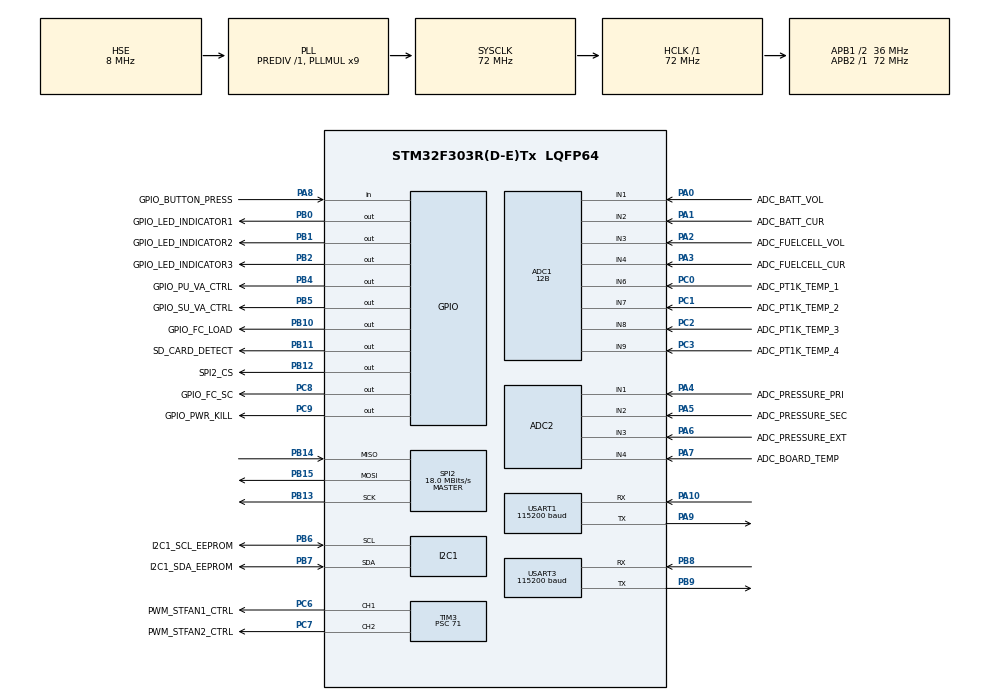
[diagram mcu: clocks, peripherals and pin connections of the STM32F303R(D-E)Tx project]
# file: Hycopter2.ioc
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ADC1.Channel-0\#ChannelRegularConversion=ADC_CHANNEL_1
ADC1.Channel-1\#ChannelRegularConversion=ADC_CHANNEL_2
ADC1.Channel-2\#ChannelRegularConversion=ADC_CHANNEL_3
ADC1.Channel-3\#ChannelRegularConversion=ADC_CHANNEL_4
ADC1.Channel-4\#ChannelRegularConversion=ADC_CHANNEL_6
ADC1.Channel-5\#ChannelRegularConversion=ADC_CHANNEL_7
ADC1.Channel-6\#ChannelRegularConversion=ADC_CHANNEL_8
ADC1.Channel-7\#ChannelRegularConversion=ADC_CHANNEL_9
ADC1.ClockPrescaler=ADC_CLOCK_ASYNC_DIV1
ADC1.ContinuousConvMode=DISABLE
ADC1.DMAContinuousRequests=ENABLE
ADC1.DataAlign=ADC_DATAALIGN_RIGHT
ADC1.DiscontinuousConvMode=DISABLE
ADC1.EOCSelection=ADC_EOC_SINGLE_CONV
ADC1.EnableAnalogWatchDog1=false
ADC1.EnableAnalogWatchDog2=false
ADC1.EnableAnalogWatchDog3=false
ADC1.EnableInjectedConversion=DISABLE
ADC1.EnableRegularConversion=ENABLE
ADC1.ExternalTrigConv=ADC_SOFTWARE_START
ADC1.ExternalTrigConvEdge=ADC_EXTERNALTRIGCONVEDGE_NONE
ADC1.LowPowerAutoWait=DISABLE
ADC1.NbrOfConversion=8
ADC1.NbrOfConversionFlag=1
ADC1.Offset-0\#ChannelRegularConversion=0
ADC1.Offset-1\#ChannelRegularConversion=0
ADC1.Offset-2\#ChannelRegularConversion=0
ADC1.Offset-3\#ChannelRegularConversion=0
ADC1.Offset-4\#ChannelRegularConversion=0
ADC1.Offset-5\#ChannelRegularConversion=0
ADC1.Offset-6\#ChannelRegularConversion=0
ADC1.Offset-7\#ChannelRegularConversion=0
ADC1.OffsetNumber-0\#ChannelRegularConversion=ADC_OFFSET_NONE
ADC1.OffsetNumber-1\#ChannelRegularConversion=ADC_OFFSET_NONE
ADC1.OffsetNumber-2\#ChannelRegularConversion=ADC_OFFSET_NONE
ADC1.OffsetNumber-3\#ChannelRegularConversion=ADC_OFFSET_NONE
ADC1.OffsetNumber-4\#ChannelRegularConversion=ADC_OFFSET_NONE
ADC1.OffsetNumber-5\#ChannelRegularConversion=ADC_OFFSET_NONE
ADC1.OffsetNumber-6\#ChannelRegularConversion=ADC_OFFSET_NONE
ADC1.OffsetNumber-7\#ChannelRegularConversion=ADC_OFFSET_NONE
ADC1.Overrun=ADC_OVR_DATA_OVERWRITTEN
ADC1.Rank-0\#ChannelRegularConversion=1
ADC1.Rank-1\#ChannelRegularConversion=2
ADC1.Rank-2\#ChannelRegularConversion=3
ADC1.Rank-3\#ChannelRegularConversion=4
ADC1.Rank-4\#ChannelRegularConversion=5
ADC1.Rank-5\#ChannelRegularConversion=6
ADC1.Rank-6\#ChannelRegularConversion=7
ADC1.Rank-7\#ChannelRegularConversion=8
ADC1.Resolution=ADC_RESOLUTION_12B
ADC1.SamplingTime-0\#ChannelRegularConversion=ADC_SAMPLETIME_601CYCLES_5
ADC1.SamplingTime-1\#ChannelRegularConversion=ADC_SAMPLETIME_601CYCLES_5
ADC1.SamplingTime-2\#ChannelRegularConversion=ADC_SAMPLETIME_601CYCLES_5
ADC1.SamplingTime-3\#ChannelRegularConversion=ADC_SAMPLETIME_601CYCLES_5
ADC1.SamplingTime-4\#ChannelRegularConversion=ADC_SAMPLETIME_601CYCLES_5
ADC1.SamplingTime-5\#ChannelRegularConversion=ADC_SAMPLETIME_601CYCLES_5
ADC1.SamplingTime-6\#ChannelRegularConversion=ADC_SAMPLETIME_601CYCLES_5
ADC1.SamplingTime-7\#ChannelRegularConversion=ADC_SAMPLETIME_601CYCLES_5
ADC1.ScanConvMode=ADC_SCAN_ENABLE
ADC1.master=1
ADC2.Channel-0\#ChannelRegularConversion=ADC_CHANNEL_1
ADC2.Channel-1\#ChannelRegularConversion=ADC_CHANNEL_2
ADC2.Channel-2\#ChannelRegularConversion=ADC_CHANNEL_3
ADC2.Channel-3\#ChannelRegularConversion=ADC_CHANNEL_4
ADC2.DMAContinuousRequests=ENABLE
ADC2.EnableInjectedConversion=DISABLE
ADC2.NbrOfConversion=4
ADC2.NbrOfConversionFlag=1
ADC2.Offset-0\#ChannelRegularConversion=0
ADC2.Offset-1\#ChannelRegularConversion=0
ADC2.Offset-2\#ChannelRegularConversion=0
ADC2.Offset-3\#ChannelRegularConversion=0
ADC2.OffsetNumber-0\#ChannelRegularConversion=ADC_OFFSET_NONE
ADC2.OffsetNumber-1\#ChannelRegularConversion=ADC_OFFSET_NONE
ADC2.OffsetNumber-2\#ChannelRegularConversion=ADC_OFFSET_NONE
ADC2.OffsetNumber-3\#ChannelRegularConversion=ADC_OFFSET_NONE
ADC2.Rank-0\#ChannelRegularConversion=1
ADC2.Rank-1\#ChannelRegularConversion=2
ADC2.Rank-2\#ChannelRegularConversion=3
ADC2.Rank-3\#ChannelRegularConversion=4
ADC2.SamplingTime-0\#ChannelRegularConversion=ADC_SAMPLETIME_601CYCLES_5
ADC2.SamplingTime-1\#ChannelRegularConversion=ADC_SAMPLETIME_601CYCLES_5
ADC2.SamplingTime-2\#ChannelRegularConversion=ADC_SAMPLETIME_601CYCLES_5
ADC2.SamplingTime-3\#ChannelRegularConversion=ADC_SAMPLETIME_601CYCLES_5
Dma.ADC1.1.Direction=DMA_PERIPH_TO_MEMORY
Dma.ADC1.1.Instance=DMA1_Channel1
Dma.ADC1.1.MemDataAlignment=DMA_MDATAALIGN_HALFWORD
Dma.ADC1.1.MemInc=DMA_MINC_ENABLE
Dma.ADC1.1.Mode=DMA_NORMAL
Dma.ADC1.1.PeriphDataAlignment=DMA_PDATAALIGN_HALFWORD
Dma.ADC1.1.PeriphInc=DMA_PINC_DISABLE
Dma.ADC1.1.Priority=DMA_PRIORITY_HIGH
Dma.ADC2.0.Direction=DMA_PERIPH_TO_MEMORY
Dma.ADC2.0.Instance=DMA2_Channel1
Dma.ADC2.0.MemDataAlignment=DMA_MDATAALIGN_HALFWORD
Dma.ADC2.0.MemInc=DMA_MINC_ENABLE
Dma.ADC2.0.Mode=DMA_NORMAL
Dma.ADC2.0.PeriphDataAlignment=DMA_PDATAALIGN_HALFWORD
Dma.ADC2.0.PeriphInc=DMA_PINC_DISABLE
Dma.ADC2.0.Priority=DMA_PRIORITY_HIGH
Dma.Request0=ADC2
Dma.Request1=ADC1
FATFS._USE_LABEL=1
Mcu.Family=STM32F3
Mcu.Name=STM32F303R(D-E)Tx
Mcu.Package=LQFP64
Mcu.UserConstants=STACK_FAN1_CC_hes_pwm,0;STACK_FAN2_CC_hes_pwm,0x0008
NVIC.ADC1_2_IRQn=true\:0\:0\:false\:false\:true\:true
NVIC.DMA1_Channel1_IRQn=true\:0\:0\:false\:false\:true\:false
NVIC.DMA2_Channel1_IRQn=true\:0\:0\:false\:false\:true\:false
NVIC.PriorityGroup=NVIC_PRIORITYGROUP_4
NVIC.USART1_IRQn=true\:0\:0\:false\:false\:true\:true
NVIC.USART3_IRQn=true\:0\:0\:false\:false\:true\:true
PA0.GPIO_Label=ADC_BATT_VOL
PA0.Mode=IN1-Single-Ended
PA0.Signal=ADC1_IN1
PA1.GPIO_Label=ADC_BATT_CUR
PA1.Mode=IN2-Single-Ended
PA1.Signal=ADC1_IN2
PA10.Mode=Asynchronous
PA10.Signal=USART1_RX
PA13.Mode=Trace_Asynchronous_SW
PA13.Signal=SYS_JTMS-SWDIO
PA14.Mode=Trace_Asynchronous_SW
PA14.Signal=SYS_JTCK-SWCLK
PA2.GPIO_Label=ADC_FUELCELL_VOL
PA2.Mode=IN3-Single-Ended
PA2.Signal=ADC1_IN3
PA3.GPIO_Label=ADC_FUELCELL_CUR
PA3.Mode=IN4-Single-Ended
PA3.Signal=ADC1_IN4
PA4.GPIO_Label=ADC_PRESSURE_PRI
PA4.Mode=IN1-Single-Ended
PA4.Signal=ADC2_IN1
PA5.GPIO_Label=ADC_PRESSURE_SEC
PA5.Mode=IN2-Single-Ended
PA5.Signal=ADC2_IN2
PA6.GPIO_Label=ADC_PRESSURE_EXT
PA6.Mode=IN3-Single-Ended
PA6.Signal=ADC2_IN3
PA7.GPIO_Label=ADC_BOARD_TEMP
PA7.Mode=IN4-Single-Ended
PA7.Signal=ADC2_IN4
PA8.GPIO_Label=GPIO_BUTTON_PRESS
PA8.Signal=GPIO_Input
PA9.Mode=Asynchronous
PA9.Signal=USART1_TX
PB0.GPIO_Label=GPIO_LED_INDICATOR1
PB0.GPIO_PuPd=GPIO_PULLUP
PB0.Signal=GPIO_Output
PB1.GPIO_Label=GPIO_LED_INDICATOR2
PB1.GPIO_PuPd=GPIO_PULLUP
PB1.Signal=GPIO_Output
PB10.GPIO_Label=GPIO_FC_LOAD
PB10.GPIO_PuPd=GPIO_PULLDOWN
PB10.Signal=GPIO_Output
PB11.GPIO_Label=SD_CARD_DETECT
PB11.Signal=GPIO_Output
PB12.GPIO_Label=SPI2_CS
PB12.Signal=GPIO_Output
PB13.Mode=Full_Duplex_Master
PB13.Signal=SPI2_SCK
PB14.Mode=Full_Duplex_Master
PB14.Signal=SPI2_MISO
PB15.Mode=Full_Duplex_Master
PB15.Signal=SPI2_MOSI
PB2.GPIO_Label=GPIO_LED_INDICATOR3
PB2.GPIO_PuPd=GPIO_PULLUP
PB2.Signal=GPIO_Output
PB3.Mode=Trace_Asynchronous_SW
PB3.Signal=SYS_JTDO-TRACESWO
PB4.GPIO_Label=GPIO_PU_VA_CTRL
PB4.GPIO_PuPd=GPIO_PULLDOWN
PB4.Signal=GPIO_Output
PB5.GPIO_Label=GPIO_SU_VA_CTRL
PB5.GPIO_PuPd=GPIO_PULLUP
PB5.PinState=GPIO_PIN_SET
PB5.Signal=GPIO_Output
PB6.GPIO_Label=I2C1_SCL_EEPROM
PB6.Mode=I2C
PB6.Signal=I2C1_SCL
PB7.GPIO_Label=I2C1_SDA_EEPROM
PB7.Mode=I2C
PB7.Signal=I2C1_SDA
PB8.Mode=Asynchronous
PB8.Signal=USART3_RX
PB9.Mode=Asynchronous
PB9.Signal=USART3_TX
PC0.GPIO_Label=ADC_PT1K_TEMP_1
PC0.Signal=ADCx_IN6
PC1.GPIO_Label=ADC_PT1K_TEMP_2
PC1.Signal=ADCx_IN7
PC2.GPIO_Label=ADC_PT1K_TEMP_3
PC2.Signal=ADCx_IN8
PC3.GPIO_Label=ADC_PT1K_TEMP_4
PC3.Signal=ADCx_IN9
PC6.GPIO_Label=PWM_STFAN1_CTRL
PC6.Signal=S_TIM3_CH1
PC7.GPIO_Label=PWM_STFAN2_CTRL
PC7.Signal=S_TIM3_CH2
PC8.GPIO_Label=GPIO_FC_SC
PC8.Signal=GPIO_Output
PC9.GPIO_Label=GPIO_PWR_KILL
PC9.GPIO_PuPd=GPIO_PULLUP
PC9.Signal=GPIO_Output
PF0-OSC_IN.Mode=HSE-External-Oscillator
PF0-OSC_IN.Signal=RCC_OSC_IN
PF1-OSC_OUT.Mode=HSE-External-Oscillator
PF1-OSC_OUT.Signal=RCC_OSC_OUT
ProjectManager.HeapSize=0x200
ProjectManager.StackSize=0x400
ProjectManager.TargetToolchain=MDK-ARM V5
RCC.AHBFreq_Value=72000000
RCC.APB1CLKDivider=RCC_HCLK_DIV2
RCC.APB1Freq_Value=36000000
RCC.APB1TimFreq_Value=72000000
RCC.APB2Freq_Value=72000000
RCC.APB2TimFreq_Value=72000000
RCC.CortexFreq_Value=72000000
RCC.HCLKFreq_Value=72000000
RCC.HSE_VALUE=8000000
RCC.HSI_VALUE=8000000
RCC.LSE_VALUE=32768
RCC.PLLMUL=RCC_PLL_MUL9
RCC.PLLSourceVirtual=RCC_PLLSOURCE_HSE
RCC.SYSCLKFreq_VALUE=72000000
RCC.SYSCLKSourceVirtual=RCC_SYSCLKSOURCE_PLLCLK
RCC.USBFreq_Value=72000000
SH.ADCx_IN6.0=ADC1_IN6,IN6-Single-Ended
SH.ADCx_IN7.0=ADC1_IN7,IN7-Single-Ended
SH.ADCx_IN8.0=ADC1_IN8,IN8-Single-Ended
SH.ADCx_IN9.0=ADC1_IN9,IN9-Single-Ended
SH.S_TIM3_CH1.0=TIM3_CH1,PWM Generation1 CH1
SH.S_TIM3_CH2.0=TIM3_CH2,PWM Generation2 CH2
SPI2.BaudRatePrescaler=SPI_BAUDRATEPRESCALER_2
SPI2.CalculateBaudRate=18.0 MBits/s
SPI2.DataSize=SPI_DATASIZE_8BIT
SPI2.Direction=SPI_DIRECTION_2LINES
SPI2.Mode=SPI_MODE_MASTER
SPI2.VirtualType=VM_MASTER
TIM3.AutoReloadPreload=TIM_AUTORELOAD_PRELOAD_ENABLE
TIM3.Channel-PWM\ Generation1\ CH1=TIM_CHANNEL_1
TIM3.Channel-PWM\ Generation2\ CH2=TIM_CHANNEL_2
TIM3.Period=50000
TIM3.Prescaler=71
USART1.BaudRate=115200
USART1.VirtualMode-Asynchronous=VM_ASYNC
USART3.BaudRate=115200
USART3.VirtualMode-Asynchronous=VM_ASYNC
VP_FATFS_VS_Generic.Mode=User_defined
board=custom

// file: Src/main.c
/**
 ******************************************************************************
 * @file           : main.c
 * @brief          : Main program body
 ******************************************************************************
 * This notice applies to any and all portions of this file
 * that are not between comment pairs USER CODE BEGIN and
 * USER CODE END. Other portions of this file, whether
 * inserted by the user or by software development tools
 * are owned by their respective copyright owners.
 *
 * Copyright (c) 2018 STMicroelectronics International N.V.
 * All rights reserved.
 *
 * Redistribution and use in source and binary forms, with or without
 * modification, are permitted, provided that the following conditions are met:
 *
 * 1. Redistribution of source code must retain the above copyright notice,
 *    this list of conditions and the following disclaimer.
 * 2. Redistributions in binary form must reproduce the above copyright notice,
 *    this list of conditions and the following disclaimer in the documentation
 *    and/or other materials provided with the distribution.
 * 3. Neither the name of STMicroelectronics nor the names of other
 *    contributors to this software may be used to endorse or promote products
 *    derived from this software without specific written permission.
 * 4. This software, including modifications and/or derivative works of this
 *    software, must execute solely and exclusively on microcontroller or
 *    microprocessor devices manufactured by or for STMicroelectronics.
 * 5. Redistribution and use of this software other than as permitted under
 *    this license is void and will automatically terminate your rights under
 *    this license.
 *
 * THIS SOFTWARE IS PROVIDED BY STMICROELECTRONICS AND CONTRIBUTORS "AS IS"
 * AND ANY EXPRESS, IMPLIED OR STATUTORY WARRANTIES, INCLUDING, BUT NOT
 * LIMITED TO, THE IMPLIED WARRANTIES OF MERCHANTABILITY, FITNESS FOR A
 * PARTICULAR PURPOSE AND NON-INFRINGEMENT OF THIRD PARTY INTELLECTUAL PROPERTY
 * RIGHTS ARE DISCLAIMED TO THE FULLEST EXTENT PERMITTED BY LAW. IN NO EVENT
 * SHALL STMICROELECTRONICS OR CONTRIBUTORS BE LIABLE FOR ANY DIRECT, INDIRECT,
 * INCIDENTAL, SPECIAL, EXEMPLARY, OR CONSEQUENTIAL DAMAGES (INCLUDING, BUT NOT
 * LIMITED TO, PROCUREMENT OF SUBSTITUTE GOODS OR SERVICES; LOSS OF USE, DATA,
 * OR PROFITS; OR BUSINESS INTERRUPTION) HOWEVER CAUSED AND ON ANY THEORY OF
 * LIABILITY, WHETHER IN CONTRACT, STRICT LIABILITY, OR TORT (INCLUDING
 * NEGLIGENCE OR OTHERWISE) ARISING IN ANY WAY OUT OF THE USE OF THIS SOFTWARE,
 * EVEN IF ADVISED OF THE POSSIBILITY OF SUCH DAMAGE.
 *
 ******************************************************************************
 */
#include "main.h"
#include "adc.h"
#include "dma.h"
#include "fatfs.h"
#include "gpio.h"
#include "i2c.h"
#include "spi.h"
#include "stm32f3xx_hal.h"
#include "tim.h"
#include "usart.h"

/* USER CODE BEGIN Includes */
#include "test_simple.h"
/* USER CODE END Includes */

/* USER CODE BEGIN PV */
/* Private variables ---------------------------------------------------------*/

/* USER CODE END PV */

void SystemClock_Config(void);

/* USER CODE BEGIN PFP */
/* Private function prototypes -----------------------------------------------*/

/* USER CODE END PFP */

int main(void) {

    /* MCU
     * Configuration----------------------------------------------------------*/

    /* Reset of all peripherals, Initializes the Flash interface and the
     * Systick. */
    HAL_Init();

    /* Configure the system clock */
    SystemClock_Config();

    /* Initialize all configured peripherals */
    MX_GPIO_Init();
    MX_DMA_Init();
    MX_ADC1_Init();
    MX_ADC2_Init();
    MX_USART1_UART_Init();
    MX_SPI2_Init();
    MX_TIM3_Init();
    MX_I2C1_Init();
    MX_USART3_UART_Init();
    MX_FATFS_Init();
    /* USER CODE BEGIN 2 */
    Test_simple();
    /* USER CODE END 2 */

    /* Infinite loop */
    while (1) {

    }
}

void SystemClock_Config(void) {

    RCC_OscInitTypeDef RCC_OscInitStruct;
    RCC_ClkInitTypeDef RCC_ClkInitStruct;
    RCC_PeriphCLKInitTypeDef PeriphClkInit;

    /**Initializes the CPU, AHB and APB busses clocks
     */
    RCC_OscInitStruct.OscillatorType =
        RCC_OSCILLATORTYPE_HSI | RCC_OSCILLATORTYPE_HSE;
    RCC_OscInitStruct.HSEState = RCC_HSE_ON;
    RCC_OscInitStruct.HSIState = RCC_HSI_ON;
    RCC_OscInitStruct.HSICalibrationValue = 16;
    RCC_OscInitStruct.PLL.PLLState = RCC_PLL_ON;
    RCC_OscInitStruct.PLL.PLLSource = RCC_PLLSOURCE_HSE;
    RCC_OscInitStruct.PLL.PLLMUL = RCC_PLL_MUL9;
    RCC_OscInitStruct.PLL.PREDIV = RCC_PREDIV_DIV1;
    if (HAL_RCC_OscConfig(&RCC_OscInitStruct) != HAL_OK) {
        _Error_Handler(__FILE__, __LINE__);
    }

    /**Initializes the CPU, AHB and APB busses clocks
     */
    RCC_ClkInitStruct.ClockType = RCC_CLOCKTYPE_HCLK | RCC_CLOCKTYPE_SYSCLK |
                                  RCC_CLOCKTYPE_PCLK1 | RCC_CLOCKTYPE_PCLK2;
    RCC_ClkInitStruct.SYSCLKSource = RCC_SYSCLKSOURCE_PLLCLK;
    RCC_ClkInitStruct.AHBCLKDivider = RCC_SYSCLK_DIV1;
    RCC_ClkInitStruct.APB1CLKDivider = RCC_HCLK_DIV2;
    RCC_ClkInitStruct.APB2CLKDivider = RCC_HCLK_DIV1;

    if (HAL_RCC_ClockConfig(&RCC_ClkInitStruct, FLASH_LATENCY_2) != HAL_OK) {
        _Error_Handler(__FILE__, __LINE__);
    }

    PeriphClkInit.PeriphClockSelection =
        RCC_PERIPHCLK_USART1 | RCC_PERIPHCLK_USART3 | RCC_PERIPHCLK_I2C1 |
        RCC_PERIPHCLK_ADC12 | RCC_PERIPHCLK_TIM34;
    PeriphClkInit.Usart1ClockSelection = RCC_USART1CLKSOURCE_PCLK2;
    PeriphClkInit.Usart3ClockSelection = RCC_USART3CLKSOURCE_PCLK1;
    PeriphClkInit.Adc12ClockSelection = RCC_ADC12PLLCLK_DIV1;
    PeriphClkInit.I2c1ClockSelection = RCC_I2C1CLKSOURCE_HSI;
    PeriphClkInit.Tim34ClockSelection = RCC_TIM34CLK_HCLK;
    if (HAL_RCCEx_PeriphCLKConfig(&PeriphClkInit) != HAL_OK) {
        _Error_Handler(__FILE__, __LINE__);
    }

    /**Configure the Systick interrupt time
     */
    HAL_SYSTICK_Config(HAL_RCC_GetHCLKFreq() / 1000);

    /**Configure the Systick
     */
    HAL_SYSTICK_CLKSourceConfig(SYSTICK_CLKSOURCE_HCLK);

    /* SysTick_IRQn interrupt configuration */
    HAL_NVIC_SetPriority(SysTick_IRQn, 0, 0);
}

void _Error_Handler(char *file, int line) {
    /* USER CODE BEGIN Error_Handler_Debug */
    /* User can add his own implementation to report the HAL error return state
     */
    while (1) {
    }
    /* USER CODE END Error_Handler_Debug */
}

#ifdef USE_FULL_ASSERT
/**
 * @brief  Reports the name of the source file and the source line number
 *         where the assert_param error has occurred.
 * @param  file: pointer to the source file name
 * @param  line: assert_param error line source number
 * @retval None
 */
void assert_failed(uint8_t *file, uint32_t line) {
    /* USER CODE BEGIN 6 */
    /* User can add his own implementation to report the file name and line
       number, tex: printf("Wrong parameters value: file %s on line %d\r\n",
       file, line) */
    /* USER CODE END 6 */
}
#endif /* USE_FULL_ASSERT */

/************************ (C) COPYRIGHT STMicroelectronics *****END OF FILE****/
